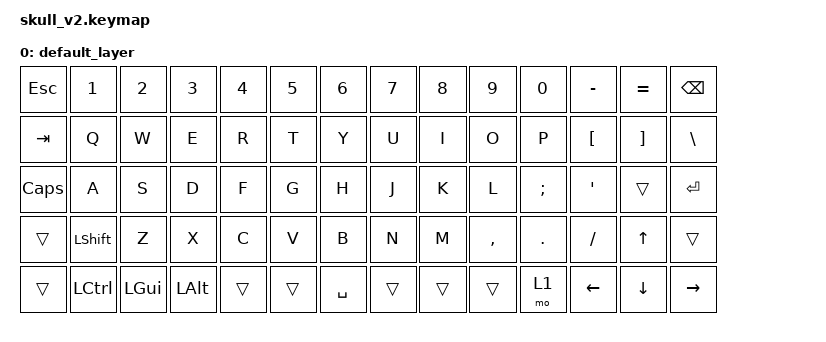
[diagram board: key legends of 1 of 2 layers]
#include <behaviors.dtsi>
#include <dt-bindings/zmk/keys.h>
#include <dt-bindings/zmk/bt.h>
#include <dt-bindings/zmk/outputs.h>
/{
        keymap {
        compatible = "zmk,keymap";

        default_layer {
            // ┌───┬───┬───┬───┬───┬───┬───┬───┬───┬───┬───┬───┬───┬───────┐
            // │ESC│ 1 │ 2 │ 3 │ 4 │ 5 │ 6 │ 7 │ 8 │ 9 │ 0 │ - │ = │ BKSPC │
            // ├───┴─┬─┴─┬─┴─┬─┴─┬─┴─┬─┴─┬─┴─┬─┴─┬─┴─┬─┴─┬─┴─┬─┴─┬─┴─┬─────┤
            // │ TAB │ Q │ W │ E │ R │ T │ Y │ U │ I │ O │ P │ [ │ ] │  \  │
            // ├─────┴┬──┴┬──┴┬──┴┬──┴┬──┴┬──┴┬──┴┬──┴┬──┴┬──┴┬──┴┬──┴─────┤
            // │ CAPS │ A │ S │ D │ F │ G │ H │ J │ K │ L │ ; │ ' │ ENTER  │
            // ├──────┴─┬─┴─┬─┴─┬─┴─┬─┴─┬─┴─┬─┴─┬─┴─┬─┴─┬─┴─┬─┴─┬─┴────────┤
            // │ SHIFT  │ Z │ X │ C │ V │ B │ N │ M │ , │ . │ / │  SHIFT   │
            // ├────┬───┴┬──┴─┬─┴───┴───┴───┴───┴───┴──┬┴───┼───┴┬────┬────┤
            // │CTRL│WIN │ALT │         SPACE          │mod1│WIN │MENU│CTRL│
            // └────┴────┴────┴────────────────────────┴────┴────┴────┴────┘

            bindings = <
                &kp ESC    &kp N1     &kp N2   &kp N3   &kp N4   &kp N5   &kp N6   &kp N7   &kp N8    &kp N9    &kp N0    &kp MINUS &kp EQUAL &kp BSPC
                &kp TAB    &kp Q      &kp W    &kp E    &kp R    &kp T    &kp Y    &kp U    &kp I     &kp O     &kp P     &kp LBKT  &kp RBKT  &kp BSLH
                &kp CLCK   &kp A      &kp S    &kp D    &kp F    &kp G    &kp H    &kp J    &kp K     &kp L     &kp SEMI  &kp APOS  &trans    &kp RET   
                &trans     &kp LSHFT  &kp Z    &kp X    &kp C    &kp V    &kp B    &kp N    &kp M    &kp COMMA &kp DOT   &kp FSLH  &kp UP    &trans    
                &trans     &kp LCTRL  &kp LGUI   &kp LALT  &trans   &trans  &kp SPACE &trans   &trans &trans  &mo 1     &kp LEFT  &kp DOWN  &kp RIGHT 
            >;
        };
        layer_1 {
            // ┌───┬───┬───┬───┬───┬───┬───┬───┬───┬───┬───┬───┬───┬───────┐
            // │BTC│BT1│BT2│BT3│BT4│BT5│OUT│   │   │   │   │   │   │ BTCLR │
            // ├───┴─┬─┴─┬─┴─┬─┴─┬─┴─┬─┴─┬─┴─┬─┴─┬─┴─┬─┴─┬─┴─┬─┴─┬─┴─┬─────┤
            // │  ~  │   │   │   │   │   │   │   │   │   │   │   │   │     │
            // ├─────┴┬──┴┬──┴┬──┴┬──┴┬──┴┬──┴┬──┴┬──┴┬──┴┬──┴┬──┴┬──┴─────┤
            // │      │   │   │   │   │   │   │   │   │   │   │   │        │
            // ├──────┴─┬─┴─┬─┴─┬─┴─┬─┴─┬─┴─┬─┴─┬─┴─┬─┴─┬─┴─┬─┴─┬─┴────────┤
            // │        │   │   │   │   │   │   │   │   │   │   │          │
            // ├────┬───┴┬──┴─┬─┴───┴───┴───┴───┴───┴──┬┴───┼───┴┬────┬────┤
            // │    │    │    │                        │    │    │    │    │
            // └────┴────┴────┴────────────────────────┴────┴────┴────┴────┘

            bindings = <
                &bt BT_CLR &bt BT_SEL 0 &bt BT_SEL 1 &bt BT_SEL 2 &bt BT_SEL 3 &bt BT_SEL 4 &out OUT_TOG &trans &trans &trans &trans &trans &trans &bt BT_CLR
                &kp GRAVE  &trans       &trans       &trans       &trans       &trans       &trans       &trans &trans &trans &trans &trans &trans &trans
                &trans     &trans       &trans       &trans       &trans       &trans       &trans       &trans &trans &trans &trans &trans &trans &trans
                &trans     &trans       &trans       &trans       &trans       &trans       &trans       &trans &trans &trans &trans &trans &trans &trans
                &trans     &trans       &trans                    &trans                                       &trans &trans &trans &trans &trans
            >;
        };
        
    };
};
